# RZT2H register map
Vendor: Renesas Electronics Corporation; Series: RZT; File version: 1.00.00
CPU: other r0p0, little endian, MPU, no FPU, VTOR, 4 interrupt priority bits, 624 interrupts
Registers are 32-bit, read-write, reset 0x0 unless marked. A register's access mark holds for its fields unless they carry their own. Offsets are from the block's base; [hi:lo] are bit positions; {n}, {i} and the like mark numbered series.

## BISS0 — BiSS-C Unit 0
Base 0x90203000
Same registers: BISS{n} {0x90203000+0x10000*n} (n=1..11), BISS12 0x90303000, BISS13 0x90313000, BISS14 0x90323000, BISS15 0x90333000
0x00 SCDATAL{i} (i=1..8; step 0x8) — Sensor Data L
0x04 SCDATAH{i} (i=1..8; step 0x8) — Sensor Data H
{0x7C+4i} RDATA{i} (i=1..16) — Register Data {i}
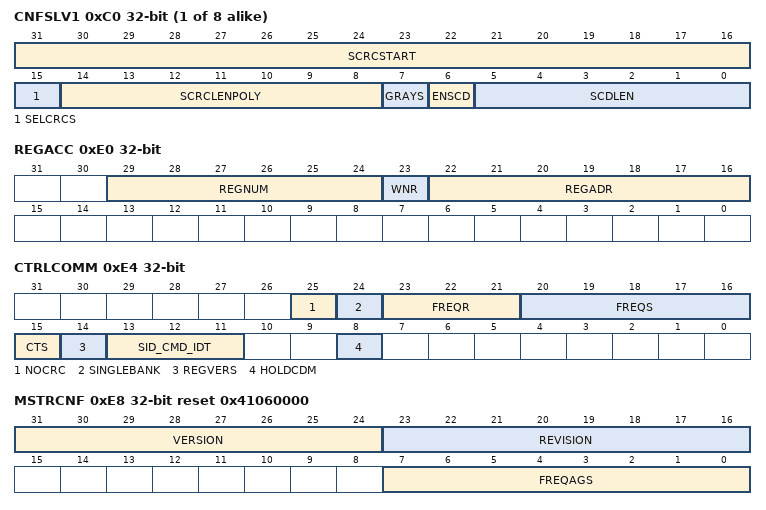
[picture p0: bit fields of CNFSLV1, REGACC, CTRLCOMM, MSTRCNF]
{0xBC+4i} CNFSLV{i} (i=1..8) — Configuration Slave {i}
  [31:16] SCRCSTART — CRC calculation start value for slave n
  [15] SELCRCS — CRC polynomial selection for slave n
    0=Apply CRC polynomial as predefined in SCRCLEN; 1=Apply CRC polynomial as individually defined in SCRCPOLY
  [14:8] SCRCLENPOLY — CRC length with predefined CRC polynomial for slave n (SCRCLEN[6:0])
  [7] GRAYS — Enable GRAY to binary conversion for SSI encoder
    0=SSI single-cycle data binary coded; 1=SSI single-cycle data GRAY coded
  [6] ENSCD — Enable single-cycle data for slave n
    0=Single-cycle data not available; 1=Single-cycle data available
  [5:0] SCDLEN — Single-cycle data length of slave n
0xE0 REGACC — Register Access
  [29:24] REGNUM — Number of consecutive registers to access
  [23] WNR — Register communication direction
    0=Read register data; 1=Write register data
  [22:16] REGADR — Register communication start address
0xE4 CTRLCOMM — Control Communication
  [25] NOCRC — Storage of received CRC in SCDATA
    0=CRC of SCD is stored in SCDATA; 1=CRC of SCD is not stored in SCDATA
  [24] SINGLEBANK — Usage of one/two RAM bank(s) for SCDATA
    0=Two RAM banks are used for SCDATA; 1=One RAM bank is used for SCDATA
  [23:21] FREQR — BiSS register data frequency
  [20:16] FREQS — Single-cycle data clock frequency at MA (fMA)
  [15] CTS — Type of control communication
    0=BiSS Commands; 1=Register communication
  [14] REGVERS — Type of protocol for register communication
    0=Not permitted; 1=Register communication BiSS-C
  [13:11] SID_CMD_IDT — Slave addressing for register communication (SLAVEID[2:0])
    0=Immediate execution; 1=The slave's feedback (IDA) is tested before execution. The BiSS command is not executed if test fails.
  [8] HOLDCDM — Behavior of MA signal at the end of frame
    0=MA changes to digital high after detecting the slave's timeout termination at SL; 1=MA remains constant until the next frame begins
0xE8 MSTRCNF reset 0x41060000 — Master Configuration
  [31:24] VERSION ro
  [23:16] REVISION ro — Design ID
  [7:0] FREQAGS — Frame repetition rate (AGS frequency divider)
0xEC CHCNF reset 0x1 — Channel Configuration
  [9:8] CFGCH1 — Channel configuration
    0=Not permitted; 1=BiSS-C; 2=SSI; 3=Channel is not used (no device connected)
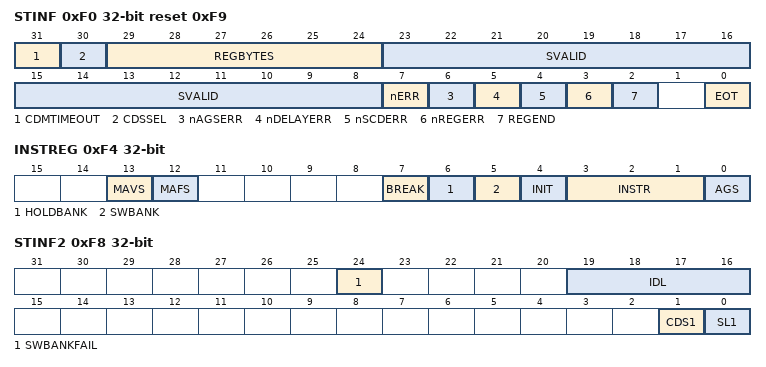
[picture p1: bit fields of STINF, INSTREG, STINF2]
0xF0 STINF reset 0xF9 — Status Information
  [31] CDMTIMEOUT ro — Control Data Master (CDM) timeout reached
    0=Timeout of BiSS-C control communication not reached; 1=Timeout of BiSS-C control communication reached
  [30] CDSSEL ro — State of Control Data Slave (CDS)
    0=CDS value 0; 1=CDS value 1
  [29:24] REGBYTES ro — Number of valid register bytes
  [23:8] SVALID — SCDATAn validity indication (n: slave, n = 1 to 8)
    0=Single-cycle data invalid; 1=Single-cycle data valid
  [7] nERR ro — State of the error interrupt (NER)
    0=Internal error occurred; 1=No error occurred
  [6] nAGSERR ro — Automatic Get Sensor (AGS) error
    0=At least one BiSS frame has been omitted; 1=No missing BiSS frames
  [5] nDELAYERR ro — Start bit in register communication
    0=Missing start bit in last register data transmission. Register address is not implemented or register access processing time too long (> 20 ms, if CTRLCOMM.FREQR = 0x05).; 1=No missing start bit in last register data transmission
  [4] nSCDERR ro — Single-cycle data (SCD) transmission error
    0=Error in last single-cycle data transmission; 1=No error in last single-cycle data transmission
  [3] nREGERR ro — Control communication error
    0=Error in last control communication; 1=No error in last control communication
  [2] REGEND ro — End of Control Communication
    0=Control communication running or not started since power on/INIT; 1=Control communication completed/not running
  [0] EOT ro — End of transmission
    0=Data transmission active; 1=Data transmission not active
0xF4 INSTREG — Instruction Register
  [13] MAVS — MA line force level
    0=Low; 1=High
  [12] MAFS — Control of the MA line
    0=MA line is not controlled; 1=MA line is forced with MAVS
  [7] BREAK — Start BREAK Sequence
    0=No operation; 1=Abort data transmission
  [6] HOLDBANK — RAM Bank Control
    0=Automatic bank switching is permitted; 1=Automatic bank switching is prevented
  [5] SWBANK — RAM Bank Switching
    0=No operation when Previous value = 0. RAM banks are switched when Previous value = 1.; 1=RAM banks are switched when Previous value = 0. No operation when Previous value = 1.
  [4] INIT — Start initialization sequence
    0=No operation; 1=Initialize (REGVERS = 1: BiSS-C)
  [3:1] INSTR — Single-Cycle Data (SCD) Control Instruction
  [0] AGS — Automatic Get Sensor Data (AGS)
    0=No automatic data transmission; 1=Automatic data transmission
0xF8 STINF2 ro (reset mask 0xFFFF0000) — Status Information 2
  [24] SWBANKFAIL — Bank switching status
    0=Bank switching (SCDATA) successful; 1=Bank switching (SCDATA) not successful
  [19:16] IDL — Number of set ID lock bits during control communication
  [1] CDS1 — Control Data Slave (CDS) bit value
    0=CDS value 0; 1=CDS value 1
  [0] SL1 — SL input line state
    0=SL line level low; 1=SL line level high
